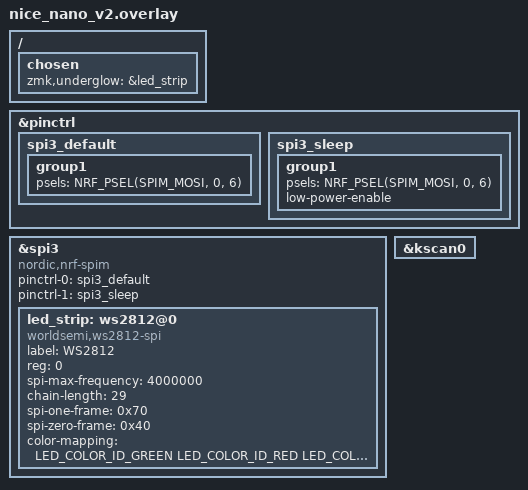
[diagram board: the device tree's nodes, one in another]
#include <dt-bindings/led/led.h>
&pinctrl {
    spi3_default: spi3_default {
        group1 {
            psels = <NRF_PSEL(SPIM_MOSI, 0, 6)>;
        };
    };
    spi3_sleep: spi3_sleep {
        group1 {
            psels = <NRF_PSEL(SPIM_MOSI, 0, 6)>;
            low-power-enable;
        };
    };
};
&spi3 {
  compatible = "nordic,nrf-spim";
  status = "okay";
  pinctrl-0 = <&spi3_default>;
  pinctrl-1 = <&spi3_sleep>;
  pinctrl-names = "default", "sleep";
  led_strip: ws2812@0 {
    compatible = "worldsemi,ws2812-spi";
    label = "WS2812";
    /* SPI */
    reg = <0>; /* ignored, but necessary for SPI bindings */
    spi-max-frequency = <4000000>;
    /* WS2812 */
    chain-length = <29>; /* number of LEDs */
    spi-one-frame = <0x70>;
    spi-zero-frame = <0x40>;
    color-mapping = <LED_COLOR_ID_GREEN
                          LED_COLOR_ID_RED
                          LED_COLOR_ID_BLUE>;
  };
};

/ {
    chosen {
        zmk,underglow = &led_strip;
    };
};

/*
 * Reset-only wake from Soft Off.
 *
 * The standard Sofle matrix kscan has `wakeup-source`, which allows matrix
 * keys (including the encoder push switches) to wake the nRF52840 from
 * Soft Off. Remove that property so the matrix cannot be a Soft Off wake
 * source. The physical RESET button remains able to wake the MCU.
 */
&kscan0 {
    /delete-property/ wakeup-source;
};
